# Musca_B1 register map
Vendor: ARM Ltd.; Series: ARMv8-M Mainline; File version: 1.0
CPU: CM33 r0p2, little endian, MPU, FPU, 4 interrupt priority bits, 8 SAU regions
Registers are 32-bit, read-write, reset 0x0 unless marked. A register's access mark holds for its fields unless they carry their own. Offsets are from the block's base; [hi:lo] are bit positions.

## GPTIMER — General-Purpose Timer
Base 0x4010C000
Same registers: GPTIMER_Secure 0x5010C000
0x00 GPTRESET ro — Control Reset Register
  [1:0] GPTRESET — CPU0 interrupt status
0x04 GPTINTM — Masked interrupt status register
  [1:0] GPTINTM — Current masked status of the interrupt
0x08 GPTINTC — Interrupt clear register
  [1:0] GPTINTC — Writing 0b1 disables the ALARM[n] interrupt
0x10 GPTALARM0 — ALARM0 data value register
  [31:0] GPTALARM0_DATA — Value that triggers the ALARM0 interrupt when the counter reaches that value
0x14 GPTALARM1 — ALARM1 data value register
  [31:0] GPTALARM1_DATA — Value that triggers the ALARM1 interrupt when the counter reaches that value
0x18 GPTINTR ro — Raw interrupt status register
  [2:0] GPTINTR — Raw interrupt state, before masking of GPTINTR interrupt
0x1C GPTCOUNTER ro — Counter data value register
  [31:0] GPTCOUNTER — Current value of 32-bit Timer Counter

## GPIO0 — General-purpose I/O 0
Base 0x41000000
Same registers: GPIO0_Secure 0x51000000
0x00 DATA
0x04 DATAOUT — Data Output Register
0x10 OUTENSET — Ouptut enable set Register
0x14 OUTENCLR — Ouptut enable clear Register
0x18 ALTFUNCSET — Alternate function set Register
0x1C ALTFUNCCLR — Alternate function clear Register
0x20 INTENSET — Interrupt enable set Register
0x24 INTENCLR — Interrupt enable clear Register
0x28 INTTYPESET — Interrupt type set Register
0x2C INTTYPECLR — Interrupt type clear Register
0x30 INTPOLSET — Polarity-level, edge interrupt configuration set Register
0x34 INTPOLCLR — Polarity-level, edge interrupt configuration clear Register
0x38 INTSTATUS ro — Interrupt Status Register
0x38 INTCLEAR wo write-1-clears (alternate view of INTSTATUS) — Interrupt CLEAR Register

## WATCHDOG — Non-secure Watchdog Timer
Base 0x40081000
Same registers: S32KWATCHDOG 0x5002E000, WATCHDOG_Secure 0x50081000
0x00 WDOGLOAD reset 0xFFFFFFFF — Watchdog Load Register
0x04 WDOGVALUE ro reset 0xFFFFFFFF — Watchdog Value Register
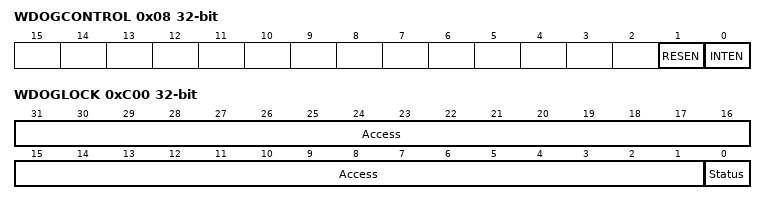
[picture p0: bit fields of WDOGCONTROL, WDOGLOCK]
0x08 WDOGCONTROL — Watchdog Control Register
  [1] RESEN — Enable watchdog reset output
    0=Disable Watchdog reset; 1=Enable Watchdog reset
  [0] INTEN — Enable the interrupt event
    0=Disable Watchdog interrupt; 1=Enable Watchdog interrupt
0x0C WDOGINTCLR wo — Watchdog Interrupt Clear Register
  [0] INT write-1-clears — Interrupt
0x10 WDOGRIS ro — Watchdog Raw Interrupt Status Register
  [0] RIS — Raw watchdog Interrupt
0x14 WDOGMIS ro — Watchdog Mask Interrupt Status Register
  [0] MIS — Masked Watchdog Interrupt
0xC00 WDOGLOCK — Watchdog Lock Register
  [31:1] Access — Enable register writes
  [0] Status — Register write enable status
    0=Enabled (Write access to all other registers is enabled. This is the default.); 1=Disabled (Write access to all other registers is disabled.)

## PWM — PWM_IP6512
Base 0x40107000
0x00 PWMCR — PWM Control Register
  [0] OUTPUT_SET — Start stop bit for the pwm_output
    1=Enabled (Generate programmed waveform on pwm_output); 0=Disabled (Set pwm_output continually high)
0x04 PWMPR — PWM Period Register. Number of system clock cycles indicating the period of PWM cycle.The minimum and maximum values have special significance. 0x0: pwm_output continually high 0xFFFFFFFF: pwm_output continually low
0x08 PWMHR — PWM High Iime Register. This register contains the number of system clock cycles for during which the pwm_output should be kept high in a PWM cycle
0x10 PWMEI wo — PWM Enable Interrupt Register
  [0] Enable_BIT — Determines whether the write accesses the Interrupt Enable register
    1=Enabled (Enable the Interrupt generation)
0x14 PWMDI wo — PWM Disable Interrupt Register
  [0] Disable_BIT — Determines whether the write accesses the Interrupt Disable register
    1=Disabled (Disable the Interrupt generation)
0x18 PWMRI ro — PWM Read Intr Enable Register.Reading from this address accesses the current state of the interrupt control registers
  [0] Enable_BIT — Check whether the Interrupt is Enabled
    1=Enabled (Interrupt is Enabled)
0x1C PWMIS ro — PWM Read Interrupt Status Register
  [0] Status — Reading from this address returns the current state of the PWM Interrupt output, and then sets the bit low
    1=Active (Interrupt is active); 0=Not active (Interrupt is not active)
